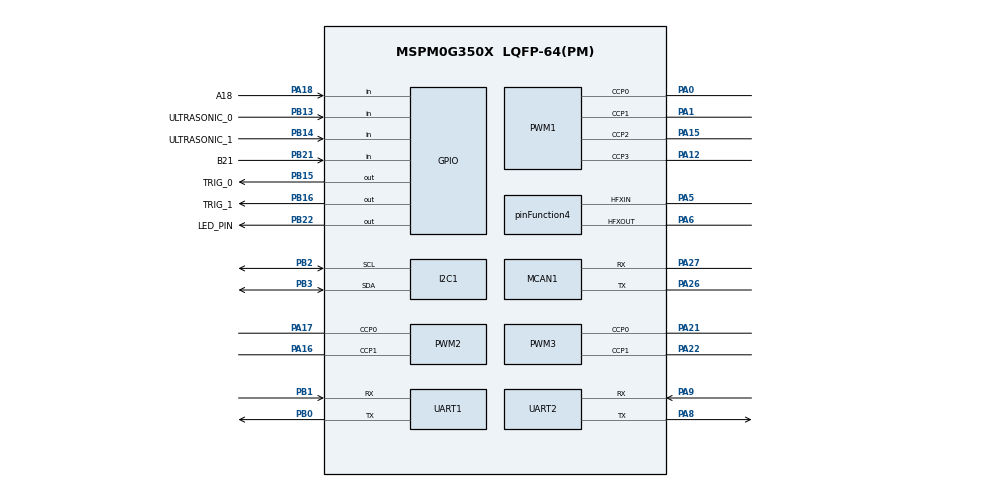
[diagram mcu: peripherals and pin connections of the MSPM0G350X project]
/**
 * @cliArgs --device "MSPM0G350X" --part "Default" --package "LQFP-64(PM)" --product "mspm0_sdk@2.10.00.04"
 * @versions {"tool":"1.26.2+4477"}
 */

/**
 * Import the modules used in this configuration.
 */
const GPIO          = scripting.addModule("/ti/driverlib/GPIO", {}, false);
const GPIO1         = GPIO.addInstance();
const GPIO2         = GPIO.addInstance();
const GPIO3         = GPIO.addInstance();
const I2C           = scripting.addModule("/ti/driverlib/I2C", {}, false);
const I2C1          = I2C.addInstance();
const MCAN          = scripting.addModule("/ti/driverlib/MCAN", {}, false);
const MCAN1         = MCAN.addInstance();
const PWM           = scripting.addModule("/ti/driverlib/PWM", {}, false);
const PWM1          = PWM.addInstance();
const PWM2          = PWM.addInstance();
const PWM3          = PWM.addInstance();
const SYSCTL        = scripting.addModule("/ti/driverlib/SYSCTL");
const SYSTICK       = scripting.addModule("/ti/driverlib/SYSTICK");
const TIMER         = scripting.addModule("/ti/driverlib/TIMER", {}, false);
const TIMER1        = TIMER.addInstance();
const UART          = scripting.addModule("/ti/driverlib/UART", {}, false);
const UART1         = UART.addInstance();
const UART2         = UART.addInstance();
const ProjectConfig = scripting.addModule("/ti/project_config/ProjectConfig");

/**
 * Write custom configuration values to the imported modules.
 */
const divider9       = system.clockTree["UDIV"];
divider9.divideValue = 2;

const multiplier2         = system.clockTree["PLL_QDIV"];
multiplier2.multiplyValue = 4;

const mux4       = system.clockTree["EXHFMUX"];
mux4.inputSelect = "EXHFMUX_XTAL";

const mux5       = system.clockTree["EXLFMUX"];
mux5.inputSelect = "EXLFMUX_XTAL";

const mux8       = system.clockTree["HSCLKMUX"];
mux8.inputSelect = "HSCLKMUX_SYSPLL0";

const mux9       = system.clockTree["LFXTMUX"];
mux9.inputSelect = "LFXTMUX_TRUE";

const mux10       = system.clockTree["MFPCLKMUX"];
mux10.inputSelect = "MFPCLKMUX_HFCLK";

const mux12       = system.clockTree["SYSPLLMUX"];
mux12.inputSelect = "zSYSPLLMUX_HFCLK";

const pinFunction4                        = system.clockTree["HFXT"];
pinFunction4.inputFreq                    = 40;
pinFunction4.enable                       = true;
pinFunction4.HFXTStartup                  = 10;
pinFunction4.peripheral.$assign           = "SYSCTL";
pinFunction4.peripheral.hfxInPin.$assign  = "PA5";
pinFunction4.peripheral.hfxOutPin.$assign = "PA6";

const pinFunction6     = system.clockTree["LFXT"];
pinFunction6.inputFreq = 32.768;
pinFunction6.enable    = true;

GPIO1.$name                              = "LED";
GPIO1.port                               = "PORTB";
GPIO1.associatedPins[0].$name            = "LED_PIN";
GPIO1.associatedPins[0].assignedPin      = "22";
GPIO1.associatedPins[0].internalResistor = "PULL_UP";
GPIO1.associatedPins[0].pin.$assign      = "PB22";

const Board = scripting.addModule("/ti/driverlib/Board", {}, false);

GPIO2.$name                              = "KEY";
GPIO2.associatedPins.create(2);
GPIO2.associatedPins[0].$name            = "A18";
GPIO2.associatedPins[0].direction        = "INPUT";
GPIO2.associatedPins[0].interruptEn      = true;
GPIO2.associatedPins[0].polarity         = "RISE";
GPIO2.associatedPins[0].pin.$assign      = "PA18";
GPIO2.associatedPins[1].$name            = "B21";
GPIO2.associatedPins[1].direction        = "INPUT";
GPIO2.associatedPins[1].internalResistor = "PULL_UP";
GPIO2.associatedPins[1].polarity         = "FALL";
GPIO2.associatedPins[1].interruptEn      = true;
GPIO2.associatedPins[1].pin.$assign      = "PB21";

GPIO3.$name                              = "ULTRASONIC";
GPIO3.associatedPins.create(4);
GPIO3.associatedPins[0].$name            = "ULTRASONIC_0";
GPIO3.associatedPins[0].direction        = "INPUT";
GPIO3.associatedPins[0].internalResistor = "PULL_DOWN";
GPIO3.associatedPins[0].interruptEn      = true;
GPIO3.associatedPins[0].polarity         = "RISE_FALL";
GPIO3.associatedPins[0].pin.$assign      = "PB13";
GPIO3.associatedPins[1].$name            = "ULTRASONIC_1";
GPIO3.associatedPins[1].internalResistor = "PULL_DOWN";
GPIO3.associatedPins[1].direction        = "INPUT";
GPIO3.associatedPins[1].polarity         = "RISE_FALL";
GPIO3.associatedPins[1].interruptEn      = true;
GPIO3.associatedPins[1].pin.$assign      = "PB14";
GPIO3.associatedPins[2].$name            = "TRIG_0";
GPIO3.associatedPins[2].pin.$assign      = "PB15";
GPIO3.associatedPins[3].$name            = "TRIG_1";
GPIO3.associatedPins[3].pin.$assign      = "PB16";

I2C1.basicEnableController             = true;
I2C1.basicControllerStandardBusSpeed   = "Fast";
I2C1.$name                             = "I2C_OLED";
I2C1.peripheral.sdaPin.$assign         = "PB3";
I2C1.peripheral.sclPin.$assign         = "PB2";
I2C1.sdaPinConfig.hideOutputInversion  = scripting.forceWrite(false);
I2C1.sdaPinConfig.onlyInternalResistor = scripting.forceWrite(false);
I2C1.sdaPinConfig.passedPeripheralType = scripting.forceWrite("Digital");
I2C1.sdaPinConfig.$name                = "ti_driverlib_gpio_GPIOPinGeneric16";
I2C1.sclPinConfig.hideOutputInversion  = scripting.forceWrite(false);
I2C1.sclPinConfig.onlyInternalResistor = scripting.forceWrite(false);
I2C1.sclPinConfig.passedPeripheralType = scripting.forceWrite("Digital");
I2C1.sclPinConfig.$name                = "ti_driverlib_gpio_GPIOPinGeneric17";

MCAN1.$name                    = "MCAN0";
MCAN1.fdMode                   = false;
MCAN1.enableInterrupt          = true;
MCAN1.spPercent                = 85;
MCAN1.desiredDataRate          = 0;
MCAN1.stdFiltType              = "10";
MCAN1.extFiltType              = "10";
MCAN1.txBufElemSize            = "DL_MCAN_ELEM_SIZE_8BYTES";
MCAN1.txBufNum                 = 8;
MCAN1.rxFIFO0size              = 8;
MCAN1.rxFIFO1OpMode            = "1";
MCAN1.rxFIFO0ElemSize          = "DL_MCAN_ELEM_SIZE_8BYTES";
MCAN1.rxFIFO1ElemSize          = "DL_MCAN_ELEM_SIZE_8BYTES";
MCAN1.interruptFlags           = ["DL_MCAN_INTERRUPT_RF0N"];
MCAN1.extFiltElem              = "001";
MCAN1.stdFiltElem              = "001";
MCAN1.interruptLine            = ["DL_MCAN_INTR_LINE_NUM_0"];
MCAN1.interruptLine0Flag       = ["DL_MCAN_INTERRUPT_RF0N"];
MCAN1.m0interrupts             = ["DL_MCAN_MSP_INTERRUPT_LINE0"];
MCAN1.txFIFOSize               = 8;
MCAN1.desiredNomRate           = 1000;
MCAN1.peripheral.rxPin.$assign = "PA27";
MCAN1.peripheral.txPin.$assign = "PA26";
MCAN1.txPinConfig.$name        = "ti_driverlib_gpio_GPIOPinGeneric0";
MCAN1.rxPinConfig.$name        = "ti_driverlib_gpio_GPIOPinGeneric1";

PWM1.clockPrescale                      = 80;
PWM1.timerStartTimer                    = true;
PWM1.$name                              = "FRONT_OUT";
PWM1.enableShadowLoad                   = true;
PWM1.ccIndex                            = [0,1,2,3];
PWM1.timerCount                         = 5000;
PWM1.PWM_CHANNEL_0.$name                = "ti_driverlib_pwm_PWMTimerCC0";
PWM1.PWM_CHANNEL_0.shadowUpdateMode     = "ZERO_EVT";
PWM1.PWM_CHANNEL_1.$name                = "ti_driverlib_pwm_PWMTimerCC1";
PWM1.PWM_CHANNEL_1.shadowUpdateMode     = "ZERO_EVT";
PWM1.ccp0PinConfig.$name                = "ti_driverlib_gpio_GPIOPinGeneric4";
PWM1.ccp0PinConfig.direction            = scripting.forceWrite("OUTPUT");
PWM1.ccp0PinConfig.hideOutputInversion  = scripting.forceWrite(false);
PWM1.ccp0PinConfig.onlyInternalResistor = scripting.forceWrite(false);
PWM1.ccp0PinConfig.passedPeripheralType = scripting.forceWrite("Digital");
PWM1.ccp0PinConfig.internalResistor     = "PULL_UP";
PWM1.ccp1PinConfig.$name                = "ti_driverlib_gpio_GPIOPinGeneric5";
PWM1.ccp1PinConfig.direction            = scripting.forceWrite("OUTPUT");
PWM1.ccp1PinConfig.hideOutputInversion  = scripting.forceWrite(false);
PWM1.ccp1PinConfig.onlyInternalResistor = scripting.forceWrite(false);
PWM1.ccp1PinConfig.passedPeripheralType = scripting.forceWrite("Digital");
PWM1.ccp1PinConfig.internalResistor     = "PULL_UP";
PWM1.peripheral.ccp0Pin.$assign         = "PA0";
PWM1.peripheral.ccp1Pin.$assign         = "PA1";
PWM1.peripheral.ccp2Pin.$assign         = "PA15";
PWM1.peripheral.ccp3Pin.$assign         = "PA12";
PWM1.PWM_CHANNEL_2.$name                = "ti_driverlib_pwm_PWMTimerCC2";
PWM1.PWM_CHANNEL_2.shadowUpdateMode     = "ZERO_EVT";
PWM1.PWM_CHANNEL_3.$name                = "ti_driverlib_pwm_PWMTimerCC3";
PWM1.PWM_CHANNEL_3.shadowUpdateMode     = "ZERO_EVT";
PWM1.ccp2PinConfig.$name                = "ti_driverlib_gpio_GPIOPinGeneric6";
PWM1.ccp2PinConfig.internalResistor     = "PULL_UP";
PWM1.ccp3PinConfig.$name                = "ti_driverlib_gpio_GPIOPinGeneric7";

PWM2.clockPrescale                      = 80;
PWM2.timerStartTimer                    = true;
PWM2.$name                              = "RL_OUT";
PWM2.enableShadowLoad                   = true;
PWM2.timerCount                         = 5000;
PWM2.peripheral.$assign                 = "TIMA1";
PWM2.peripheral.ccp0Pin.$assign         = "PA17";
PWM2.peripheral.ccp1Pin.$assign         = "PA16";
PWM2.PWM_CHANNEL_0.$name                = "ti_driverlib_pwm_PWMTimerCC4";
PWM2.PWM_CHANNEL_1.$name                = "ti_driverlib_pwm_PWMTimerCC5";
PWM2.PWM_CHANNEL_1.shadowUpdateMode     = "ZERO_EVT";
PWM2.ccp0PinConfig.direction            = scripting.forceWrite("OUTPUT");
PWM2.ccp0PinConfig.hideOutputInversion  = scripting.forceWrite(false);
PWM2.ccp0PinConfig.onlyInternalResistor = scripting.forceWrite(false);
PWM2.ccp0PinConfig.passedPeripheralType = scripting.forceWrite("Digital");
PWM2.ccp0PinConfig.$name                = "ti_driverlib_gpio_GPIOPinGeneric8";
PWM2.ccp1PinConfig.direction            = scripting.forceWrite("OUTPUT");
PWM2.ccp1PinConfig.hideOutputInversion  = scripting.forceWrite(false);
PWM2.ccp1PinConfig.onlyInternalResistor = scripting.forceWrite(false);
PWM2.ccp1PinConfig.passedPeripheralType = scripting.forceWrite("Digital");
PWM2.ccp1PinConfig.$name                = "ti_driverlib_gpio_GPIOPinGeneric9";

PWM3.$name                              = "RR_OUT";
PWM3.timerStartTimer                    = true;
PWM3.clockPrescale                      = 80;
PWM3.enableShadowLoad                   = true;
PWM3.timerCount                         = 5000;
PWM3.peripheral.$assign                 = "TIMG6";
PWM3.peripheral.ccp0Pin.$assign         = "PA21";
PWM3.peripheral.ccp1Pin.$assign         = "PA22";
PWM3.PWM_CHANNEL_0.$name                = "ti_driverlib_pwm_PWMTimerCC6";
PWM3.PWM_CHANNEL_0.shadowUpdateMode     = "ZERO_EVT";
PWM3.PWM_CHANNEL_1.$name                = "ti_driverlib_pwm_PWMTimerCC7";
PWM3.PWM_CHANNEL_1.shadowUpdateMode     = "ZERO_EVT";
PWM3.ccp0PinConfig.direction            = scripting.forceWrite("OUTPUT");
PWM3.ccp0PinConfig.hideOutputInversion  = scripting.forceWrite(false);
PWM3.ccp0PinConfig.onlyInternalResistor = scripting.forceWrite(false);
PWM3.ccp0PinConfig.passedPeripheralType = scripting.forceWrite("Digital");
PWM3.ccp0PinConfig.$name                = "ti_driverlib_gpio_GPIOPinGeneric10";
PWM3.ccp1PinConfig.direction            = scripting.forceWrite("OUTPUT");
PWM3.ccp1PinConfig.hideOutputInversion  = scripting.forceWrite(false);
PWM3.ccp1PinConfig.onlyInternalResistor = scripting.forceWrite(false);
PWM3.ccp1PinConfig.passedPeripheralType = scripting.forceWrite("Digital");
PWM3.ccp1PinConfig.$name                = "ti_driverlib_gpio_GPIOPinGeneric11";

SYSCTL.forceDefaultClkConfig = true;
SYSCTL.clockTreeEn           = true;

SYSTICK.periodEnable    = true;
SYSTICK.period          = 80000;
SYSTICK.interruptEnable = true;
SYSTICK.systickEnable   = true;

TIMER1.timerClkDiv        = 8;
TIMER1.interrupts         = ["LOAD"];
TIMER1.timerStartTimer    = true;
TIMER1.$name              = "US_TIMER";
TIMER1.timerMode          = "PERIODIC";
TIMER1.timerPeriod        = "0";
TIMER1.peripheral.$assign = "TIMG12";

UART1.$name                          = "UART_0";
UART1.targetBaudRate                 = 115200;
UART1.calculatedBaudRate             = 1;
UART1.enabledDMATXTriggers           = "DL_UART_DMA_INTERRUPT_TX";
UART1.enabledDMARXTriggers           = "DL_UART_DMA_INTERRUPT_RX";
UART1.rxFifoThreshold                = "DL_UART_RX_FIFO_LEVEL_ONE_ENTRY";
UART1.enableFIFO                     = true;
UART1.rxTimeoutValue                 = 10;
UART1.enabledInterrupts              = ["DMA_DONE_RX","DMA_DONE_TX","EOT_DONE"];
UART1.peripheral.rxPin.$assign       = "PB1";
UART1.peripheral.txPin.$assign       = "PB0";
UART1.txPinConfig.$name              = "ti_driverlib_gpio_GPIOPinGeneric2";
UART1.rxPinConfig.$name              = "ti_driverlib_gpio_GPIOPinGeneric3";
UART1.DMA_CHANNEL_TX.$name           = "DMA_CH0";
UART1.DMA_CHANNEL_TX.addressMode     = "b2f";
UART1.DMA_CHANNEL_TX.srcLength       = "BYTE";
UART1.DMA_CHANNEL_TX.dstLength       = "BYTE";
UART1.DMA_CHANNEL_TX.enableInterrupt = true;
UART1.DMA_CHANNEL_RX.$name           = "DMA_CH1";
UART1.DMA_CHANNEL_RX.addressMode     = "f2b";
UART1.DMA_CHANNEL_RX.srcLength       = "BYTE";
UART1.DMA_CHANNEL_RX.dstLength       = "BYTE";
UART1.DMA_CHANNEL_RX.transferSize    = 4096;
UART1.DMA_CHANNEL_RX.enableInterrupt = true;

UART2.$name                          = "UART_1";
UART2.enabledDMATXTriggers           = "DL_UART_DMA_INTERRUPT_TX";
UART2.enabledDMARXTriggers           = "DL_UART_DMA_INTERRUPT_RX";
UART2.rxFifoThreshold                = "DL_UART_RX_FIFO_LEVEL_ONE_ENTRY";
UART2.enableFIFO                     = true;
UART2.rxTimeoutValue                 = 10;
UART2.enabledInterrupts              = ["DMA_DONE_RX","DMA_DONE_TX","EOT_DONE"];
UART2.peripheral.$assign             = "UART1";
UART2.peripheral.rxPin.$assign       = "PA9";
UART2.peripheral.txPin.$assign       = "PA8";
UART2.txPinConfig.$name              = "ti_driverlib_gpio_GPIOPinGeneric12";
UART2.rxPinConfig.$name              = "ti_driverlib_gpio_GPIOPinGeneric13";
UART2.DMA_CHANNEL_TX.$name           = "DMA_CH2";
UART2.DMA_CHANNEL_TX.addressMode     = "b2f";
UART2.DMA_CHANNEL_TX.srcLength       = "BYTE";
UART2.DMA_CHANNEL_TX.dstLength       = "BYTE";
UART2.DMA_CHANNEL_TX.enableInterrupt = true;
UART2.DMA_CHANNEL_RX.$name           = "DMA_CH3";
UART2.DMA_CHANNEL_RX.addressMode     = "f2b";
UART2.DMA_CHANNEL_RX.srcLength       = "BYTE";
UART2.DMA_CHANNEL_RX.dstLength       = "BYTE";
UART2.DMA_CHANNEL_RX.transferSize    = 4096;
UART2.DMA_CHANNEL_RX.enableInterrupt = true;

ProjectConfig.genLibCMSIS = true;

/**
 * Pinmux solution for unlocked pins/peripherals. This ensures that minor changes to the automatic solver in a future
 * version of the tool will not impact the pinmux you originally saw.  These lines can be completely deleted in order to
 * re-solve from scratch.
 */
pinFunction6.peripheral.$suggestSolution           = "SYSCTL";
pinFunction6.peripheral.lfxInPin.$suggestSolution  = "PA3";
pinFunction6.peripheral.lfxOutPin.$suggestSolution = "PA4";
Board.peripheral.$suggestSolution                  = "DEBUGSS";
Board.peripheral.swclkPin.$suggestSolution         = "PA20";
Board.peripheral.swdioPin.$suggestSolution         = "PA19";
I2C1.peripheral.$suggestSolution                   = "I2C1";
MCAN1.peripheral.$suggestSolution                  = "CANFD0";
PWM1.peripheral.$suggestSolution                   = "TIMA0";
UART1.peripheral.$suggestSolution                  = "UART0";
UART1.DMA_CHANNEL_TX.peripheral.$suggestSolution   = "DMA_CH3";
UART1.DMA_CHANNEL_RX.peripheral.$suggestSolution   = "DMA_CH2";
UART2.DMA_CHANNEL_TX.peripheral.$suggestSolution   = "DMA_CH1";
UART2.DMA_CHANNEL_RX.peripheral.$suggestSolution   = "DMA_CH0";
